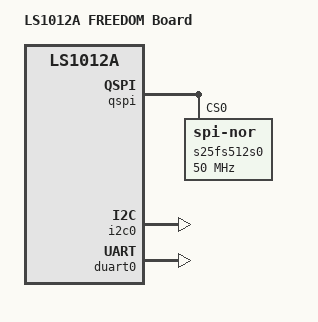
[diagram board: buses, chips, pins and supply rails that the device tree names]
// SPDX-License-Identifier: GPL-2.0+ OR X11
/*
 * Device Tree file for Freescale Layerscape-1012A family SoC.
 *
 * Copyright 2016, Freescale Semiconductor
 */

/include/ "fsl-ls1012a.dtsi"

/ {
	model = "LS1012A FREEDOM Board";
	aliases {
		spi0 = &qspi;
	};
};

&qspi {
	status = "okay";

	s25fs512s0: flash@0 {
		#address-cells = <1>;
		#size-cells = <1>;
		compatible = "jedec,spi-nor";
		spi-max-frequency = <50000000>;
		reg = <0>;
	};
};

&i2c0 {
	status = "okay";
};

&duart0 {
	status = "okay";
};
